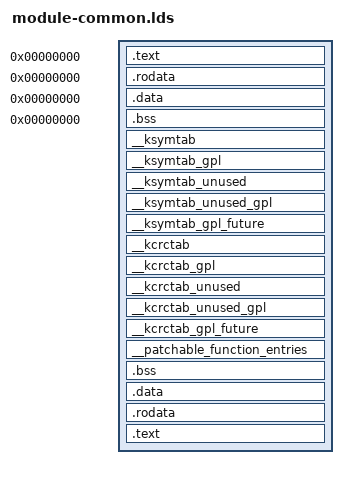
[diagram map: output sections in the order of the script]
/*
 * Common module linker script, always used when linking a module.
 * Archs are free to supply their own linker scripts.  ld will
 * combine them automatically.
 */

/* .data.foo are generated by gcc itself with -fdata-sections,
 * whereas double-dot sections (like .data..percpu) are generated
 * by kernel's magic macros.
 *
 * Since this script does not specify what to do with double-dot sections,
 * ld -r will coalesce all .data..foo input sections into one .data..foo
 * output section, all .data..bar input sections into one .data..bar
 * output section and so on. This is exactly what we want.
 *
 * Same goes for .text, .bss and .rodata. In case of .rodata, various
 * .rodata.foo sections are generated by gcc even without -fdata-sections
 */

SECTIONS {

	/* Coalesce sections produced by gcc -ffunction-sections */
	.text   0 : AT(0) { *(.text .text.[A-Za-z0-9_$]*) }

	/* Coalesce sections produced by gcc -fdata-sections */
	.rodata 0 : AT(0) { *(.rodata .rodata.[A-Za-z0-9_$]*) }
	.data   0 : AT(0) { *(.data .data.[A-Za-z0-9_$]*) }
	.bss    0 : AT(0) { *(.bss .bss.[A-Za-z0-9_$]*) }

	/DISCARD/ : { *(.discard) }

	__ksymtab		: { *(SORT(___ksymtab+*)) }
	__ksymtab_gpl		: { *(SORT(___ksymtab_gpl+*)) }
	__ksymtab_unused	: { *(SORT(___ksymtab_unused+*)) }
	__ksymtab_unused_gpl	: { *(SORT(___ksymtab_unused_gpl+*)) }
	__ksymtab_gpl_future	: { *(SORT(___ksymtab_gpl_future+*)) }
	__kcrctab		: { *(SORT(___kcrctab+*)) }
	__kcrctab_gpl		: { *(SORT(___kcrctab_gpl+*)) }
	__kcrctab_unused	: { *(SORT(___kcrctab_unused+*)) }
	__kcrctab_unused_gpl	: { *(SORT(___kcrctab_unused_gpl+*)) }
	__kcrctab_gpl_future	: { *(SORT(___kcrctab_gpl_future+*)) }

	__patchable_function_entries : { *(__patchable_function_entries) }

	/*
	 * With CONFIG_LTO_CLANG, LLD always enables -fdata-sections and
	 * -ffunction-sections, which increases the size of the final module.
	 * Merge the split sections in the final binary.
	 */
	.bss : {
		*(.bss .bss.[0-9a-zA-Z_]*)
		*(.bss..L*)
	}

	.data : {
		*(.data .data.[0-9a-zA-Z_]*)
		*(.data..L*)
	}

	.rodata : {
		*(.rodata .rodata.[0-9a-zA-Z_]*)
		*(.rodata..L*)
	}

	.text : { *(.text .text.[0-9a-zA-Z_]*) }
}
